VERSION ""

NS_ :

BS_:

BU_: Others VCU

BO_ 2564485379 vin_resp: 8 VCU

BO_ 2564502513 uds_rx_func: 8 Others

BO_ 2564428017 uds_rx: 8 Others

BO_ 2564485392 uds_tx: 8 VCU

BO_ 2147485481 ccp_rx: 8 Others

BO_ 2147485497 ccp_tx: 8 Vector__XXX

BO_ 2147484199 ccp_daq_8: 8 VCU

BO_ 2147484198 ccp_daq_7: 8 VCU

BO_ 2147484197 ccp_daq_6: 8 VCU

BO_ 2147484196 ccp_daq_5: 8 VCU

BO_ 2147484195 ccp_daq_4: 8 VCU

BO_ 2147484194 ccp_daq_3: 8 VCU

BO_ 2147484193 ccp_daq_2: 8 VCU

BO_ 2147484192 ccp_daq_1: 8 VCU

BO_ 2147484185 ccp_daq_0: 8 VCU

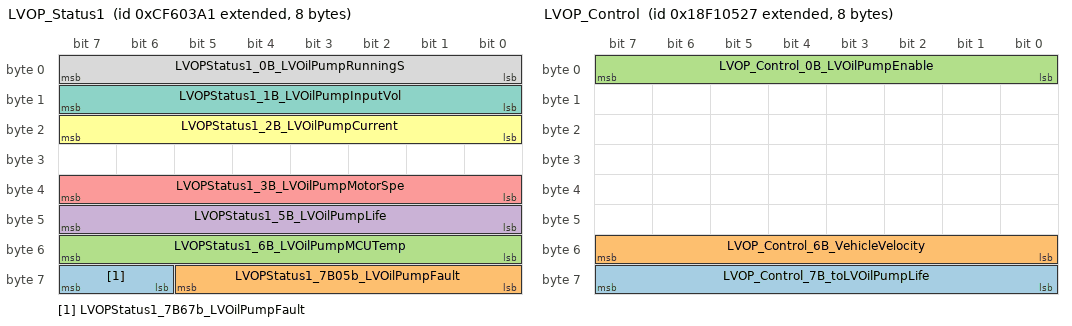
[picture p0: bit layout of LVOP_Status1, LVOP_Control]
BO_ 2364933025 LVOP_Status1: 8 Others
 SG_ LVOPStatus1_7B67b_LVOilPumpFault : 62|2@1+ (1,0) [0|0] "" Vector__XXX
 SG_ LVOPStatus1_7B05b_LVOilPumpFault : 56|6@1+ (1,0) [0|0] "" Vector__XXX
 SG_ LVOPStatus1_6B_LVOilPumpMCUTemp : 48|8@1+ (1,-40) [0|0] "" Vector__XXX
 SG_ LVOPStatus1_5B_LVOilPumpLife : 40|8@1+ (1,0) [0|0] "" Vector__XXX
 SG_ LVOPStatus1_3B_LVOilPumpMotorSpe : 32|8@1+ (10,0) [0|0] "" Vector__XXX
 SG_ LVOPStatus1_2B_LVOilPumpCurrent : 16|8@1+ (1,0) [0|0] "" Vector__XXX
 SG_ LVOPStatus1_1B_LVOilPumpInputVol : 8|8@1+ (1,0) [0|0] "" Vector__XXX
 SG_ LVOPStatus1_0B_LVOilPumpRunningS : 0|8@1+ (1,0) [0|0] "" Vector__XXX

BO_ 2565932327 LVOP_Control: 8 VCU
 SG_ LVOP_Control_7B_toLVOilPumpLife : 56|8@1+ (1,0) [0|0] "" Vector__XXX
 SG_ LVOP_Control_6B_VehicleVelocity : 48|8@1+ (1,0) [0|0] "" Vector__XXX
 SG_ LVOP_Control_0B_LVOilPumpEnable : 0|8@1+ (1,0) [0|0] "" Vector__XXX

BO_TX_BU_ 2147485481 : VCU,Others;

BA_DEF_ SG_  "SigType" ENUM  "Default","Range","RangeSigned","ASCII","Discrete","Control","ReferencePGN","DTC","StringDelimiter","StringLength","StringLengthControl","MessageCounter","MessageChecksum";
BA_DEF_ SG_  "GenSigEVName" STRING ;
BA_DEF_ SG_  "GenSigILSupport" ENUM  "No","Yes";
BA_DEF_ SG_  "GenSigSendType" ENUM  "Cyclic","OnWrite","OnWriteWithRepetition","OnChange","OnChangeWithRepetition","IfActive","IfActiveWithRepetition","NoSigSendType";
BA_DEF_ SG_  "GenSigStartValue" INT 0 2147483647;
BA_DEF_ BO_  "GenMsgILSupport" ENUM  "No","Yes";
BA_DEF_ BU_  "NmStationAddress" INT 0 255;
BA_DEF_ BO_  "GenMsgSendType" ENUM  "cyclic","NotUsed","IfActive","NotUsed","NotUsed","NotUsed","NotUsed","NotUsed","noMsgSendType";
BA_DEF_ BO_  "GenMsgRequestable" INT 0 1;
BA_DEF_ BO_  "GenMsgCycleTime" INT 0 3600000;
BA_DEF_  "DBName" STRING ;
BA_DEF_  "BusType" STRING ;
BA_DEF_  "ProtocolType" STRING ;
BA_DEF_ BO_  "VFrameFormat" ENUM  "StandardCAN","ExtendedCAN","reserved","J1939PG";
BA_DEF_ SG_  "SystemSignalLongSymbol" STRING ;
BA_DEF_DEF_  "SigType" "Default";
BA_DEF_DEF_  "GenSigEVName" "Env@Nodename_@Signame";
BA_DEF_DEF_  "GenSigILSupport" "Yes";
BA_DEF_DEF_  "GenSigSendType" "NoSigSendType";
BA_DEF_DEF_  "GenSigStartValue" 0;
BA_DEF_DEF_  "GenMsgILSupport" "Yes";
BA_DEF_DEF_  "NmStationAddress" 254;
BA_DEF_DEF_  "GenMsgSendType" "noMsgSendType";
BA_DEF_DEF_  "GenMsgRequestable" 1;
BA_DEF_DEF_  "GenMsgCycleTime" 0;
BA_DEF_DEF_  "DBName" "";
BA_DEF_DEF_  "BusType" "CAN";
BA_DEF_DEF_  "ProtocolType" "J1939";
BA_DEF_DEF_  "VFrameFormat" "J1939PG";
BA_DEF_DEF_  "SystemSignalLongSymbol" "";
BA_ "DBName" "WSD5060HR1EV_B_CAN_v10";
BA_ "NmStationAddress" BU_ Others 0;
BA_ "NmStationAddress" BU_ VCU 0;
BA_ "GenMsgCycleTime" BO_ 2364933025 200;
BA_ "GenMsgCycleTime" BO_ 2565932327 100;
BA_ "SystemSignalLongSymbol" SG_ 2364933025 LVOPStatus1_7B67b_LVOilPumpFault "LVOPStatus1_7B67b_LVOilPumpFaultGrade";
BA_ "SystemSignalLongSymbol" SG_ 2364933025 LVOPStatus1_7B05b_LVOilPumpFault "LVOPStatus1_7B05b_LVOilPumpFaultCode";
BA_ "GenSigStartValue" SG_ 2364933025 LVOPStatus1_6B_LVOilPumpMCUTemp 40;
BA_ "SystemSignalLongSymbol" SG_ 2364933025 LVOPStatus1_3B_LVOilPumpMotorSpe "LVOPStatus1_3B_LVOilPumpMotorSpeed";
BA_ "SystemSignalLongSymbol" SG_ 2364933025 LVOPStatus1_1B_LVOilPumpInputVol "LVOPStatus1_1B_LVOilPumpInputVoltage";
BA_ "SystemSignalLongSymbol" SG_ 2364933025 LVOPStatus1_0B_LVOilPumpRunningS "LVOPStatus1_0B_LVOilPumpRunningState";
